# ISD9300_v3 register map
File version: 1.0
Registers are 32-bit, read-write, reset 0x0 unless marked. A register's access mark holds for its fields unless they carry their own. Offsets are from the block's base; [hi:lo] are bit positions.

## BODTALM — BOD Register Map
Base 0x40084000
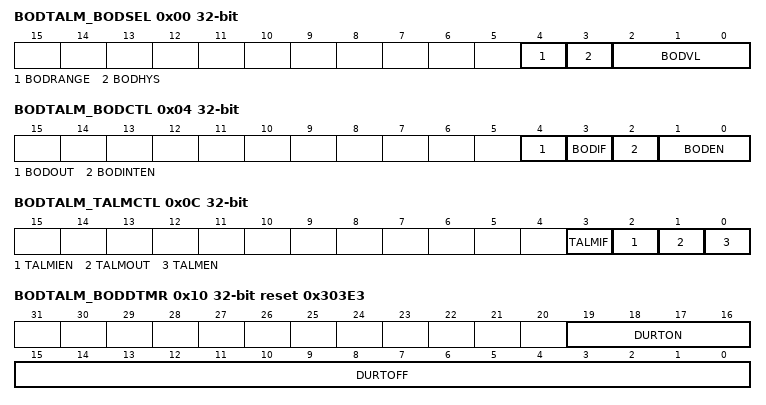
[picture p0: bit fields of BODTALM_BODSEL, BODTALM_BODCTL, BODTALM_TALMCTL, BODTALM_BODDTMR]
0x00 BODTALM_BODSEL — Brown Out Detector Select Register
  [4] BODRANGE — Range. Range setting for BODVL
  [3] BODHYS — BOD Hysteresis
    0=Hysteresis Disabled; 1=Enable Hysteresis of BOD detection
  [2:0] BODVL — BOD Voltage Level. RANGE aaa 0. 111b aaa 4.6V. 110b aaa 3.0V. 101b aaa 2.8V. 100b aaa 2.65V. 011b aaa 2.5V. 010b aaa 2.4V. 001b aaa 2.2V. 000b aaa 2.1V. RANGE aaa 1. 111b aaa 4.2V. 110b aaa 3.9V. 101b aaa 3.8V. 100b aaa 3.7V. 011b aaa 3.6V. 010b aaa 3.4V. 001b aaa 3.2V. 00 000b aaa 3.1V
0x04 BODTALM_BODCTL (reset mask 0xFFFFFF00) — Brown Out Detector Enable Register
  [4] BODOUT — Output Of BOD Detection Block. This signal can be monitored to determine the current state of the BOD comparator. BODOUT aaa 1 implies that VCC is less than BODVL.
  [3] BODIF — Current Status Of Interrupt
  [2] BODINTEN — BOD Interrupt Enable
    0=Disable BOD Interrupt; 1=Enable BOD Interrupt
  [1:0] BODEN — BOD Enable. 1xb aaa Enable continuous BOD detection. 01b aaa Enable time multiplexed BOD detection. See BODTALM_BODDTMR register. 00b aaa Disable BOD Detection.
0x08 BODTALM_TALMSEL — Temperature Alarm Select Register
  [3:0] TALMVL — Temperature Alarm Sense Level. 0000:105C. 0001:115C. 0010:125C. 0100:135C. 1000:145C
0x0C BODTALM_TALMCTL (reset mask 0xFFFFFF00) — Temperature Alarm Enable Register
  [3] TALMIF — Current Status Of Interrupt. Latched whenever a Temperature Sense event occurs and IE aaa 1. Write '1' to clear.
  [2] TALMIEN — TALARM Interrupt Enable
    0=Disable TALARM Interrupt; 1=Enable TALARM Interrupt
  [1] TALMOUT — Output Of TALARM Block. Can be polled to determine whether TALARM active (be 1).
  [0] TALMEN — TALARM Enable
    0=Disable TALARM Detection; 1=Enable TALARM Detection
0x10 BODTALM_BODDTMR reset 0x303E3 — Brown Out Detector Timer Register
  [19:16] DURTON — Time BOD Detector Is Active (DURTON+1) * 100us. Minimum value is 1. (default is 400us)
  [15:0] DURTOFF — Time BOD Detector Is Off (DURTOFF+1)*100us . Minimum value is 7. (default is 99.6ms)

## TMR0 — TMR Register Map
Base 0x40010000
Same registers: TMR1 0x40010020
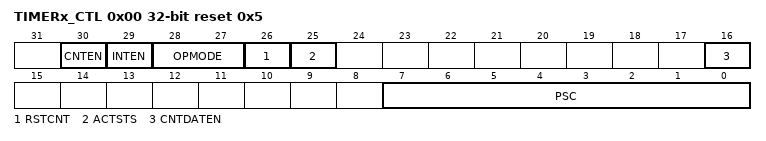
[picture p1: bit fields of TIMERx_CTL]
0x00 TIMERx_CTL reset 0x5 — Timer Control and Status Register
  [30] CNTEN — Counter Enable Bit. Note1: Setting CNTEN aaa 1 enables 24-bit counter. It continues count from last value. Note2: This bit is auto-cleared by hardware in one-shot mode (OPMODE aaa 00b) when the timer interrupt is generated (INTEN aaa 1b).
    0=Stops/Suspends counting; 1=Starts counting
  [29] INTEN — Interrupt Enable Bit. If timer interrupt is enabled, the timer asserts its interrupt signal when the count is equal to TIMERx_CMP.
    0=Disable TIMER Interrupt; 1=Enable TIMER Interrupt
  [28:27] OPMODE — Timer Operating Mode
    0=The timer is operating in the one-shot mode. The associated interrupt signal is generated once (if INTEN is enabled) and CNTEN is automatically cleared by hardware; 1=The timer is operating in the periodic mode. The associated interrupt signal is generated periodically (if INTEN is enabled); 3=The timer is operating in continuous counting mode. The associated interrupt signal is generated when CNT = TIMERx_CMP (if INTEN is enabled); however, the 24-bit up-counter counts continuously without reset
  [26] RSTCNT — Counter Reset Bit. Set this bit will reset the timer counter, pre-scale and also force CNTEN to 0.
    0=No effect; 1=Reset Timer's pre-scale counter, internal 24-bit up-counter and CNTEN bit
  [25] ACTSTS ro — Timer Active Status Bit (Read Only). This bit indicates the counter status of timer.
    0=Timer is not active; 1=Timer is active
  [16] CNTDATEN — Data Latch Enable. When CNTDATEN is set, TIMERx_CNT (Timer Data Register) will be updated continuously with the 24-bit up-counter value as the timer is counting.
    0=Timer Data Register update disable; 1=Timer Data Register update enable
  [7:0] PSC — Pre-Scale Counter. Clock input is divided by PSC+1 before it is fed to the counter. If PSC aaa 0, then there is no scaling.
0x04 TIMERx_CMP — Timer Compare Register
  [24:0] CMPDAT — Timer Comparison Value. CMPDAT is a 24-bit comparison register. When the 24-bit up-counter is enabled and its value is equal to CMPDAT value, a Timer Interrupt is requested if the timer interrupt is enabled with TIMERx_CTL.INTEN aaa 1. The CMPDAT value defines the timer cycle time. Time out period aaa (Period of timer clock input) * (8-bit PSC + 1) * (24-bit CMPDAT). NOTE1: Never set CMPDAT to 0x000 or 0x001. Timer will not function correctly. NOTE2: Regardless of CEN state, whenever a new value is written to this register, TIMER will restart counting using this new value and abort previous count.
0x08 TIMERx_INTSTS — Timer Interrupt Status Register
  [0] TIF — Timer Interrupt Flag. This bit indicates the interrupt status of Timer. TIF bit is set by hardware when the 24-bit counter matches the timer comparison value (CMPDAT). It is cleared by writing 1.
0x0C TIMERx_CNT — Timer Data Register
  [23:0] CNT — Timer Data Register. When TIMERx_CTL.CNTDATEN is set to 1, the internal 24-bit timer up-counter value will be latched into CNT. User can read this register for the up-counter value.
